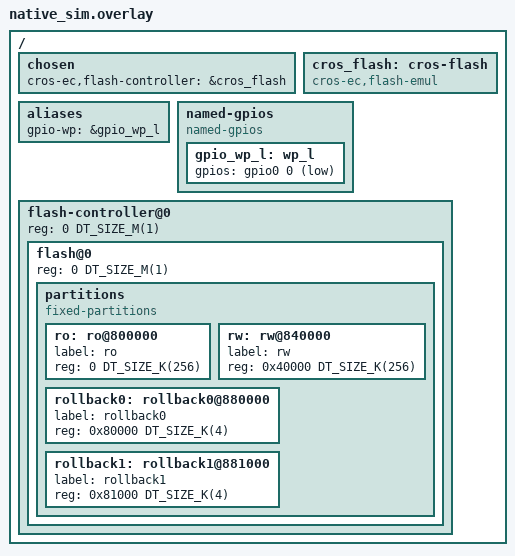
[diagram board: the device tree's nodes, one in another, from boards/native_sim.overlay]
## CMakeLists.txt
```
# Copyright 2024 The ChromiumOS Authors
# Use of this source code is governed by a BSD-style license that can be
# found in the LICENSE file.

cmake_minimum_required(VERSION 3.13.1)
find_package(Zephyr REQUIRED HINTS "${ZEPHYR_BASE}")
project(rwsig)

zephyr_include_directories(include)

target_sources(app PRIVATE
	src/rwsig.c
)

add_subdirectory(${PLATFORM_EC}/zephyr/test/test_utils test_utils)
```

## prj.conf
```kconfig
# Copyright 2024 The ChromiumOS Authors
# Use of this source code is governed by a BSD-style license that can be
# found in the LICENSE file.

CONFIG_ZTEST=y
CONFIG_ZTEST_ASSERT_VERBOSE=1
CONFIG_ASSERT=y

CONFIG_PLATFORM_EC=y
CONFIG_CROS_EC=y
CONFIG_SHIMMED_TASKS=y

CONFIG_FLASH=y
CONFIG_FLASH_SIMULATOR_EXPLICIT_ERASE=n
CONFIG_PLATFORM_EC_FLASH_SIZE_BYTES=0x200000
CONFIG_CROS_EC_RO_MEM_OFF=0x0
CONFIG_CROS_EC_RO_SIZE=0x40000
CONFIG_CROS_EC_RW_MEM_OFF=0x40000
CONFIG_CROS_EC_RW_SIZE=0x40000

CONFIG_PLATFORM_EC_HOSTCMD=y
CONFIG_PLATFORM_EC_RWSIG=y
CONFIG_PLATFORM_EC_RSA_KEY_SIZE=2048
CONFIG_PLATFORM_EC_RSA_EXPONENT_3=y
CONFIG_PLATFORM_EC_ROLLBACK=y
CONFIG_PLATFORM_EC_ROLLBACK_SECRET_SIZE=32

CONFIG_PLATFORM_EC_CONSOLE_CMD_CHARGEN=n
```

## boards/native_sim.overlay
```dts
/* Copyright 2024 The ChromiumOS Authors
 * Use of this source code is governed by a BSD-style license that can be
 * found in the LICENSE file.
 */

#include <board-overlays/native_sim.dts>
#include <cros/binman.dtsi>

/ {
	chosen {
		cros-ec,flash-controller = &cros_flash;
		/delete-property/ zephyr,code-partition;
	};

	cros_flash: cros-flash {
		compatible = "cros-ec,flash-emul";
	};

	aliases {
		gpio-wp = &gpio_wp_l;
		/delete-property/ led0;
	};

	named-gpios {
		compatible = "named-gpios";
		gpio_wp_l: wp_l {
			gpios = <&gpio0 0 (GPIO_INPUT | GPIO_ACTIVE_LOW)>;
		};
	};

	/delete-node/ leds;

	flash-controller@0 {
		reg = <0 DT_SIZE_M(1)>;

		flash@0 {
			reg = <0 DT_SIZE_M(1)>;

			/delete-node/ partitions;

			partitions {
				compatible = "fixed-partitions";
				#address-cells = <1>;
				#size-cells = <1>;

				ro: ro@800000 {
					label = "ro";
					reg = <0 DT_SIZE_K(256)>;
				};
				rw: rw@840000 {
					label = "rw";
					reg = <0x40000 DT_SIZE_K(256)>;
				};
				rollback0: rollback0@880000 {
					label = "rollback0";
					reg = <0x80000 DT_SIZE_K(4)>;
				};
				rollback1: rollback1@881000 {
					label = "rollback1";
					reg = <0x81000 DT_SIZE_K(4)>;
				};
			};
		};
	};
};
```

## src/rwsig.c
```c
/* Copyright 2024 The ChromiumOS Authors
 * Use of this source code is governed by a BSD-style license that can be
 * found in the LICENSE file.
 */
#include "common/rollback_private.h"
#include "emul/emul_flash.h"
#include "flash.h"
#include "host_command.h"
#include "rollback.h"
#include "rsa.h"
#include "rwsig.h"
#include "system.h"
#include "task.h"
#include "vb21_struct.h"
#include "vboot.h"

#include <zephyr/device.h>
#include <zephyr/fff.h>
#include <zephyr/ztest.h>

FAKE_VALUE_FUNC(int32_t, system_get_rollback_version, enum ec_image);
FAKE_VALUE_FUNC(int, system_is_locked);
FAKE_VOID_FUNC(system_disable_jump);
FAKE_VALUE_FUNC(int, system_run_image_copy, enum ec_image);
FAKE_VALUE_FUNC(int, power_button_is_pressed);

#define FFF_FAKES_LIST(FAKE)              \
	FAKE(system_get_rollback_version) \
	FAKE(system_is_locked)            \
	FAKE(system_disable_jump)         \
	FAKE(system_run_image_copy)       \
	FAKE(power_button_is_pressed)

int rwsig_check_signature(void);

/*
 * Test data, generated from this key.
-----BEGIN PRIVATE KEY-----
MIIEvgIBADANBgkqhkiG9w0BAQEFAASCBKgwggSkAgEAAoIBAQDMteWYVTyMQVTQ
mAOFZLSMRJ3HjZfQsHWjbFfXVnnAE+VbO2/DoLbI3sFSZnMZv/ZCP05tQyMkg6Re
lHiOfpByiHGBTAr3iMUxjpPweZ2r7YyflsTslTAb7zW6kkvCzlXQOmHypUGiAJ51
z/CvrsmiOxUuPRMQlnD9c50SNQTffjuucgKr9b6j+zJx/DIIwtapEjgV6bLOnEq9
mPSn7ZMfNJCPX4E6NHJahtxWILohOQAkyeNkuhNltYHq0/r9pDOE+cj7WVRoSHN/
4x5QiGZH8fiB5/3MaMW0CfrYwuekJvPiAWc/mQpH4zjI3m+QJS4jleW5Hla0Bhi0
p4b7Ud4FAgEDAoIBAQCIeUO6432y1jiLEAJY7c2y2Gkvs7qLIE5s8uU6OaaADUOS
J5/XwHnbPyuMREy71U7W1N7zghdtrRg/DaW0VGBMWvZWMrH6Wy4hCbf1pmkdSQhq
ZINIY3Vn9M58YYfXNDk1fEFMbivBVb75NUsfydvBfLjJfgy1uaCo974MI1iU/Z+h
KNX596ApP4oDJEYsJ2fj/wZkhPywQjkp0Fw1kgp11zCAlnatWz0h8dWVWykbely6
ur2DmflMLgByllMZwIAm2TQ1a6mgEikDdPIGmKPW/EAlMvjDUDjUo6eigM8WI7MC
Kk18tWBUA/kUsfTDMEOVmZ44bAFqIcwdhEbEhsYrAoGBAP2KwVWYOJrfukMijCnQ
uWEh4b+1RBBaHZ6PWpT+wTPp3pQ4z6HgAbRUae65Ux/UGttgnI8UeIGAvTDXUghz
RIYfSLl5ckT/1VhPKdngXbqbGhGUNpWSy88i/Rc5mQWkbG+JUnyS1rd7he4L6Ijy
7uM9j9NB2JGzvyPpORhJo/uRAoGBAM6x82wcybOGYaBKuZ71zlmxMe7J3idsG1Zv
hdVY0U+EkzOVri1WKeJTMi08xNyj5pmsFTgK2pvys1BnoHXjvu0ra0ExxZD4V92r
idlmRbXqXYa15PMUpKFSF2graKtehPfVb3ZxskJOV1Ud6vd4beWFn6Uio8LhFEKf
KASK47k1AoGBAKkHK45lexHqfCzBssaLJkDBQSp42Armvmm05w3/K3fxPw17NRaV
Vng4Rp8mN2qNZzzrEwoNpaurKMs6NrBM2FlqMHumTC3/45A0xpFAPnxnZrZizw5h
3TTB/g97u1kYSEpbjFMMjyT9A/QH8FtMn0IpCozWkGEif21GJhAxF/0LAoGBAInL
951ohneu68Ax0RSj3uZ2IUnb6W+dZ471A+OQi4pYYiJjyXOOxpbiIXN92JMX7xEd
Y3qx5xKhzOBFFaPtKfNyR4DL2QtQOpPHsTuZg86cPlnOmKINwxY2ukVyRceUWKU4
9PmhIYGJj44T8fpQSUOuam4XF9dAuCxqGq2x7SYjAoGBANLHzy3kBEtPBR1rtPZF
CXKqZqxvAmY7NGWHXT2YfHYKkgQMvr5zaMrgf1hPwwoCgTMvkdmWvLR/bLvMlU2Z
jucPR/m4iBxayvNNKpEF0E9ZmQ9guT2CpjsanSDTBkQbErdggMtLUcK5gBVUR4ej
uiRYcwAuTvCMyM4U1zUaVDqU
-----END PRIVATE KEY-----
 */

const static struct vb21_packed_key public_key_header = {
	.c = {
		.magic = VB21_MAGIC_PACKED_KEY,
		.struct_version_major = VB21_PACKED_KEY_VERSION_MAJOR,
		.struct_version_minor = VB21_PACKED_KEY_VERSION_MINOR,
		.total_size = sizeof(struct vb21_packed_key) + 520,
		.fixed_size = sizeof(struct vb21_packed_key),
		.desc_size = 0,
	},
	.key_offset = sizeof(struct vb21_packed_key),
	.key_size = sizeof(struct rsa_public_key),
	.sig_alg = 6,
	.hash_alg = 2,
	.key_version = 1,
};

const static unsigned char public_key[] = {
	0x40, 0x00, 0x00, 0x00, 0x33, 0xc1, 0x43, 0x9f, 0x05, 0xde, 0x51, 0xfb,
	0x86, 0xa7, 0xb4, 0x18, 0x06, 0xb4, 0x56, 0x1e, 0xb9, 0xe5, 0x95, 0x23,
	0x2e, 0x25, 0x90, 0x6f, 0xde, 0xc8, 0x38, 0xe3, 0x47, 0x0a, 0x99, 0x3f,
	0x67, 0x01, 0xe2, 0xf3, 0x26, 0xa4, 0xe7, 0xc2, 0xd8, 0xfa, 0x09, 0xb4,
	0xc5, 0x68, 0xcc, 0xfd, 0xe7, 0x81, 0xf8, 0xf1, 0x47, 0x66, 0x88, 0x50,
	0x1e, 0xe3, 0x7f, 0x73, 0x48, 0x68, 0x54, 0x59, 0xfb, 0xc8, 0xf9, 0x84,
	0x33, 0xa4, 0xfd, 0xfa, 0xd3, 0xea, 0x81, 0xb5, 0x65, 0x13, 0xba, 0x64,
	0xe3, 0xc9, 0x24, 0x00, 0x39, 0x21, 0xba, 0x20, 0x56, 0xdc, 0x86, 0x5a,
	0x72, 0x34, 0x3a, 0x81, 0x5f, 0x8f, 0x90, 0x34, 0x1f, 0x93, 0xed, 0xa7,
	0xf4, 0x98, 0xbd, 0x4a, 0x9c, 0xce, 0xb2, 0xe9, 0x15, 0x38, 0x12, 0xa9,
	0xd6, 0xc2, 0x08, 0x32, 0xfc, 0x71, 0x32, 0xfb, 0xa3, 0xbe, 0xf5, 0xab,
	0x02, 0x72, 0xae, 0x3b, 0x7e, 0xdf, 0x04, 0x35, 0x12, 0x9d, 0x73, 0xfd,
	0x70, 0x96, 0x10, 0x13, 0x3d, 0x2e, 0x15, 0x3b, 0xa2, 0xc9, 0xae, 0xaf,
	0xf0, 0xcf, 0x75, 0x9e, 0x00, 0xa2, 0x41, 0xa5, 0xf2, 0x61, 0x3a, 0xd0,
	0x55, 0xce, 0xc2, 0x4b, 0x92, 0xba, 0x35, 0xef, 0x1b, 0x30, 0x95, 0xec,
	0xc4, 0x96, 0x9f, 0x8c, 0xed, 0xab, 0x9d, 0x79, 0xf0, 0x93, 0x8e, 0x31,
	0xc5, 0x88, 0xf7, 0x0a, 0x4c, 0x81, 0x71, 0x88, 0x72, 0x90, 0x7e, 0x8e,
	0x78, 0x94, 0x5e, 0xa4, 0x83, 0x24, 0x23, 0x43, 0x6d, 0x4e, 0x3f, 0x42,
	0xf6, 0xbf, 0x19, 0x73, 0x66, 0x52, 0xc1, 0xde, 0xc8, 0xb6, 0xa0, 0xc3,
	0x6f, 0x3b, 0x5b, 0xe5, 0x13, 0xc0, 0x79, 0x56, 0xd7, 0x57, 0x6c, 0xa3,
	0x75, 0xb0, 0xd0, 0x97, 0x8d, 0xc7, 0x9d, 0x44, 0x8c, 0xb4, 0x64, 0x85,
	0x03, 0x98, 0xd0, 0x54, 0x41, 0x8c, 0x3c, 0x55, 0x98, 0xe5, 0xb5, 0xcc,
	0x21, 0x34, 0x1a, 0x55, 0x3d, 0xfc, 0x32, 0xe9, 0x8d, 0x62, 0xfe, 0xdd,
	0x91, 0x1f, 0x74, 0xf7, 0x8b, 0x84, 0x9c, 0xa4, 0xbe, 0x92, 0xac, 0xd1,
	0x09, 0x21, 0x1d, 0x04, 0x9e, 0xb7, 0x9a, 0x03, 0x20, 0xa8, 0xc6, 0xb7,
	0x85, 0xb5, 0x61, 0x49, 0x6c, 0x8d, 0xc5, 0x7b, 0x3f, 0xa3, 0x84, 0xf4,
	0x0c, 0xd6, 0xac, 0xb4, 0x67, 0x68, 0x8c, 0x4d, 0x24, 0x26, 0xaa, 0x23,
	0xef, 0x2f, 0xf1, 0xac, 0xcf, 0x1d, 0xf4, 0x9b, 0x08, 0xd5, 0xb1, 0x47,
	0xf6, 0x59, 0xd3, 0x30, 0xd3, 0x04, 0x61, 0xf0, 0x0d, 0xe0, 0x7e, 0x90,
	0x0c, 0x9f, 0x24, 0xc2, 0x25, 0xf5, 0x53, 0x5d, 0x45, 0xf1, 0xf1, 0xd1,
	0x59, 0xdd, 0x8e, 0x92, 0xb8, 0x3d, 0x19, 0x8c, 0x1f, 0x17, 0x91, 0x79,
	0x3e, 0x4a, 0x31, 0x5b, 0x35, 0x3b, 0xb6, 0xbb, 0xe1, 0x79, 0x9b, 0x87,
	0xa6, 0x51, 0xa7, 0xbc, 0x39, 0xe7, 0x78, 0x7d, 0x4a, 0x7b, 0x56, 0x4c,
	0x80, 0xf3, 0x74, 0x18, 0x88, 0xf6, 0xc5, 0xff, 0x93, 0xa4, 0x0c, 0xed,
	0x3e, 0xb3, 0x2a, 0x1c, 0x80, 0xd5, 0xb3, 0x14, 0x40, 0x48, 0x9e, 0xea,
	0xc9, 0xfd, 0x60, 0xbd, 0xc4, 0x72, 0x67, 0x99, 0xa9, 0x23, 0x5a, 0xd7,
	0x1e, 0xf4, 0x0f, 0xc0, 0xeb, 0x29, 0xa0, 0x64, 0xc8, 0xaa, 0xe0, 0x13,
	0x9f, 0x88, 0x62, 0x3f, 0xdc, 0xc0, 0xe8, 0xc8, 0x86, 0xce, 0xa7, 0xc1,
	0x46, 0xeb, 0x4d, 0x4f, 0xf3, 0xdc, 0x59, 0x10, 0x22, 0x0c, 0xd3, 0x4c,
	0xc3, 0xd7, 0xec, 0xb7, 0xa8, 0xc6, 0x68, 0xde, 0x7e, 0x55, 0x0d, 0x00,
	0xd9, 0x47, 0x58, 0xe0, 0x32, 0xd2, 0xff, 0x49, 0xcf, 0xdf, 0x13, 0x75,
	0xbe, 0x55, 0x92, 0x35, 0x5a, 0xd4, 0x89, 0x5b, 0xf4, 0x27, 0xc7, 0xba,
	0xcb, 0xb3, 0xfe, 0x6c, 0xe8, 0x58, 0xcf, 0x08, 0xdf, 0xdc, 0xcd, 0x68,
	0x38, 0x6b, 0x78, 0x3c
};

const static struct vb21_signature sig_header = {
	.c = {
		.magic = VB21_MAGIC_SIGNATURE,
		.struct_version_major = VB21_PACKED_KEY_VERSION_MAJOR,
		.struct_version_minor = VB21_PACKED_KEY_VERSION_MINOR,
		.total_size = sizeof(struct vb21_signature) + RSANUMBYTES,
		.fixed_size = sizeof(struct vb21_signature),
		.desc_size = 0,
	},
	.sig_offset = sizeof(struct vb21_signature),
	.sig_size = RSANUMBYTES,
	.data_size = 4096,
	.sig_alg = 6,
	.hash_alg = 2,
};

/* RSA signature of 4096 zeroes */
const static unsigned char signature[] = {
	0x1a, 0x7d, 0x00, 0x4a, 0x51, 0x18, 0x65, 0x55, 0x00, 0x06, 0x7b, 0x46,
	0x75, 0xa0, 0x7e, 0x43, 0x99, 0x16, 0x20, 0x54, 0xda, 0xc5, 0x5f, 0xa7,
	0x3f, 0xcf, 0x7c, 0xd9, 0xe3, 0x6a, 0xc2, 0x5f, 0x96, 0x54, 0x8c, 0x4a,
	0x2a, 0xbd, 0x34, 0xb0, 0x23, 0x87, 0x8d, 0x1c, 0xf2, 0xd6, 0x3f, 0x57,
	0x65, 0xa3, 0x36, 0xe9, 0x8e, 0xcd, 0x7a, 0x1e, 0x55, 0xa3, 0xbe, 0xd7,
	0x37, 0x73, 0x45, 0xcd, 0x46, 0xec, 0xd2, 0xdb, 0x0a, 0xdc, 0xa9, 0xa8,
	0x7b, 0xa8, 0xa3, 0x01, 0x93, 0x12, 0xeb, 0x19, 0x02, 0xba, 0x51, 0xca,
	0x94, 0x74, 0xde, 0xd2, 0x8d, 0xc3, 0x4b, 0xc5, 0xea, 0x3e, 0xba, 0xd8,
	0xc6, 0x7c, 0x2c, 0x84, 0x13, 0x54, 0x72, 0xdd, 0x8f, 0x7a, 0xb8, 0x7a,
	0x96, 0x77, 0xd1, 0xe4, 0xa5, 0xd5, 0xdd, 0x21, 0xbb, 0x86, 0x66, 0x07,
	0xfd, 0xa4, 0x8b, 0xfb, 0x84, 0xd9, 0x57, 0x14, 0xfe, 0xe9, 0x68, 0x77,
	0x9b, 0x33, 0x83, 0xf0, 0xb4, 0xa1, 0x2f, 0x43, 0xff, 0x65, 0x43, 0xff,
	0x47, 0x5a, 0x6f, 0xb1, 0xca, 0xf5, 0xcb, 0xd5, 0x84, 0xe9, 0xd3, 0xea,
	0x50, 0x85, 0x85, 0xd4, 0xc9, 0x35, 0xce, 0xc8, 0x8b, 0x8d, 0x58, 0x4e,
	0x3c, 0x3d, 0x98, 0x61, 0x5f, 0x15, 0xa5, 0x8d, 0xbd, 0x77, 0x8e, 0x36,
	0x93, 0x94, 0x77, 0xa4, 0xee, 0xf4, 0x85, 0xd8, 0x4e, 0x34, 0xe8, 0xca,
	0x08, 0x6a, 0xce, 0x32, 0x6a, 0x18, 0x75, 0x4a, 0xb6, 0x84, 0x51, 0x4c,
	0xa4, 0x8c, 0x44, 0xcb, 0xfd, 0x45, 0xef, 0xfd, 0x0a, 0xb4, 0x20, 0x92,
	0xbf, 0x15, 0xb5, 0x8a, 0x95, 0x47, 0xf3, 0x72, 0x93, 0x15, 0x33, 0xd0,
	0x94, 0x0b, 0xcf, 0xeb, 0x73, 0x32, 0x74, 0x44, 0xe2, 0x13, 0x1f, 0xdf,
	0x10, 0xff, 0xbf, 0xe6, 0xa9, 0x53, 0x97, 0xad, 0x4e, 0x2d, 0x27, 0x0e,
	0xf4, 0xc4, 0x29, 0x43
};

#define SIG_OFFSET (CONFIG_EC_WRITABLE_STORAGE_OFF + RW_SIG_OFFSET)

ZTEST(rwsig, test_invalid_key)
{
	/* fail if key incorrect */
	crec_flash_physical_write(CONFIG_RO_PUBKEY_STORAGE_OFF, 1, "\xff");
	zassert_false(rwsig_check_signature());
	zassert_equal(system_disable_jump_fake.call_count, 1);
}

ZTEST(rwsig, test_invalid_signature)
{
	/* erase the first byte of signature */
	crec_flash_physical_write(SIG_OFFSET + sig_header.sig_offset, 1,
				  "\xff");
	zassert_false(rwsig_check_signature());
	zassert_equal(system_disable_jump_fake.call_count, 1);
}

ZTEST(rwsig, test_invalid_signature_header)
{
	/* fail if signature incorrect */
	crec_flash_physical_write(
		CONFIG_EC_WRITABLE_STORAGE_OFF + RW_SIG_OFFSET, 1, "\xff");
	zassert_false(rwsig_check_signature());
	zassert_equal(system_disable_jump_fake.call_count, 1);
}

ZTEST(rwsig, test_bad_padding)
{
	/* fail if unused area is not filled with 0xFF */
	crec_flash_physical_write(CONFIG_EC_WRITABLE_STORAGE_OFF + 4096, 1,
				  "\x00");
	zassert_false(rwsig_check_signature());
	zassert_equal(system_disable_jump_fake.call_count, 1);
}

ZTEST(rwsig, test_check_signature)
{
	zassert_true(rwsig_check_signature());
}

ZTEST(rwsig, test_rollback_update)
{
	/* set the rollback version of rw framware to 2 */
	system_get_rollback_version_fake.return_val = 2;

	/* assert minimum system rollback version is 1 */
	zassert_equal(rollback_get_minimum_version(), 1);

	/* after rwsig_check_signature(), minimum rollback
	 * version should be updated */
	zassert_true(rwsig_check_signature());
	zassert_equal(rollback_get_minimum_version(), 2);
}

ZTEST(rwsig, test_rollback_update_fail)
{
	/* set the rollback version of rw framware to 0 */
	system_get_rollback_version_fake.return_val = 0;

	/* assert minimum system rollback version is 1 */
	zassert_equal(rollback_get_minimum_version(), 1);

	/* expect update fail because rw firmware has lower
	 * rollback version */
	zassert_false(rwsig_check_signature());
	zassert_equal(system_disable_jump_fake.call_count, 1);
}

void rwsig_jump_now(void);

ZTEST(rwsig, test_rwsig_jump_now)
{
	/* system_locked + rw not locked -> won't jump */
	RESET_FAKE(system_run_image_copy)
	system_is_locked_fake.return_val = 1;
	cros_flash_emul_protect_reset();
	rwsig_jump_now();
	zassert_equal(system_run_image_copy_fake.call_count, 0);

	/* system unlocked -> always jump */
	RESET_FAKE(system_run_image_copy)
	system_is_locked_fake.return_val = 0;
	cros_flash_emul_protect_reset();
	rwsig_jump_now();
	zassert_equal(system_run_image_copy_fake.call_count, 1);

	/* system_locked + rw locked -> jump */
	RESET_FAKE(system_run_image_copy)
	system_is_locked_fake.return_val = 1;
	cros_flash_emul_enable_protect();
	rwsig_jump_now();
	zassert_equal(system_run_image_copy_fake.call_count, 1);
}

#define TASK_EVENT_ABORT TASK_EVENT_CUSTOM_BIT(0)
#define TASK_EVENT_CONTINUE TASK_EVENT_CUSTOM_BIT(1)

ZTEST(rwsig, test_hostcmd_rwsig_action)
{
	struct ec_params_rwsig_action param = { .action = RWSIG_ACTION_ABORT };
	struct host_cmd_handler_args args =
		BUILD_HOST_COMMAND_PARAMS(EC_CMD_RWSIG_ACTION, 0, param);
	atomic_t *events = task_get_event_bitmap(TASK_ID_RWSIG);

	*events = 0;
	zassert_ok(host_command_process(&args));
	zassert_equal(*events, TASK_EVENT_ABORT);

	*events = 0;
	param.action = RWSIG_ACTION_CONTINUE;
	zassert_ok(host_command_process(&args));
	zassert_equal(*events, TASK_EVENT_CONTINUE);

	param.action = 99;
	zassert_equal(host_command_process(&args), EC_RES_INVALID_PARAM);
}

ZTEST(rwsig, test_rwsig_host_command_jump_rw)
{
	struct ec_params_reboot_ec reboot_params = {
		.cmd = EC_REBOOT_JUMP_RW,
	};
	struct host_cmd_handler_args reboot_args =
		BUILD_HOST_COMMAND_PARAMS(EC_CMD_REBOOT_EC, 0, reboot_params);

	RESET_FAKE(system_run_image_copy)
	system_is_locked_fake.return_val = 1;
	/* Make sure sysjump is not allowed if system is locked. */
	zassert_equal(host_command_process(&reboot_args), EC_RES_ACCESS_DENIED);
}

ZTEST(rwsig, test_rwsig_console_command_jump_rw)
{
	const struct shell *shell_zephyr = get_ec_shell();

	RESET_FAKE(system_run_image_copy)
	system_is_locked_fake.return_val = 1;
	zassert_equal(shell_execute_cmd(shell_zephyr, "sysjump RW"),
		      EC_ERROR_ACCESS_DENIED);
}

int system_run_image_copy_with_flags(enum ec_image copy,
				     uint32_t add_reset_flags);
ZTEST(rwsig, test_rwsig_sysjump_when_locked)
{
	system_is_locked_fake.return_val = 1;
	/* RWSIG task is not started. Make sure it's not allowed to jump. */
	zassert_equal(system_run_image_copy_with_flags(EC_IMAGE_RW, 0),
		      EC_ERROR_ACCESS_DENIED);
}

ZTEST(rwsig, test_rwsig_denied_flash)
{
	int ret;
	uint8_t tmp[CONFIG_FLASH_WRITE_SIZE] = { 0 };

	system_is_locked_fake.return_val = 1;
	/* RWSIG task is not started. Flash operations are not allowed. */
	ret = crec_flash_erase(CONFIG_EC_WRITABLE_STORAGE_OFF,
			       CONFIG_FLASH_ERASE_SIZE);
	zassert_equal(ret, EC_RES_BUSY);
	ret = crec_flash_erase(CONFIG_EC_WRITABLE_STORAGE_OFF + CONFIG_RW_SIZE -
				       CONFIG_FLASH_ERASE_SIZE,
			       CONFIG_FLASH_ERASE_SIZE);
	zassert_equal(ret, EC_RES_BUSY);
	ret = crec_flash_write(CONFIG_EC_WRITABLE_STORAGE_OFF,
			       CONFIG_FLASH_WRITE_SIZE, tmp);
	zassert_equal(ret, EC_RES_BUSY);
	ret = crec_flash_write(CONFIG_EC_WRITABLE_STORAGE_OFF + CONFIG_RW_SIZE -
				       CONFIG_FLASH_WRITE_SIZE,
			       CONFIG_FLASH_WRITE_SIZE, tmp);
	zassert_equal(ret, EC_RES_BUSY);
}

static void rwsig_before(void *f)
{
	const struct rollback_data initial_rollback = {
		.id = 0,
		.rollback_min_version = 1,
		.secret = {},
		.cookie = CROS_EC_ROLLBACK_COOKIE,
	};
	/* fake rw firmware, 4kB of zeroes */
	const static char fake_rw[4096] = {};

	/* Use crec_flash_physical_* instead of crec_flash_* to avoid RWSIG
	 * check. */
	crec_flash_physical_erase(CONFIG_EC_WRITABLE_STORAGE_OFF,
				  CONFIG_RW_SIZE);

	crec_flash_physical_write(CONFIG_EC_WRITABLE_STORAGE_OFF,
				  sizeof(fake_rw), fake_rw);
	crec_flash_physical_write(CONFIG_ROLLBACK_OFF, sizeof(initial_rollback),
				  (const char *)&initial_rollback);
	crec_flash_physical_write(CONFIG_ROLLBACK_OFF + CONFIG_FLASH_ERASE_SIZE,
				  sizeof(initial_rollback),
				  (const char *)&initial_rollback);

	crec_flash_physical_write(CONFIG_RO_PUBKEY_STORAGE_OFF,
				  sizeof(public_key_header),
				  (const char *)&public_key_header);
	crec_flash_physical_write(CONFIG_RO_PUBKEY_STORAGE_OFF +
					  public_key_header.key_offset,
				  sizeof(public_key), public_key);
	crec_flash_physical_write(SIG_OFFSET, sizeof(sig_header),
				  (const char *)&sig_header);
	crec_flash_physical_write(SIG_OFFSET + sig_header.sig_offset,
				  sizeof(signature), signature);

	FFF_FAKES_LIST(RESET_FAKE);
	FFF_RESET_HISTORY();
	system_get_rollback_version_fake.return_val = 1;
	system_is_locked_fake.return_val = 1;
}

ZTEST_SUITE(rwsig, NULL, NULL, rwsig_before, NULL, NULL);
```
